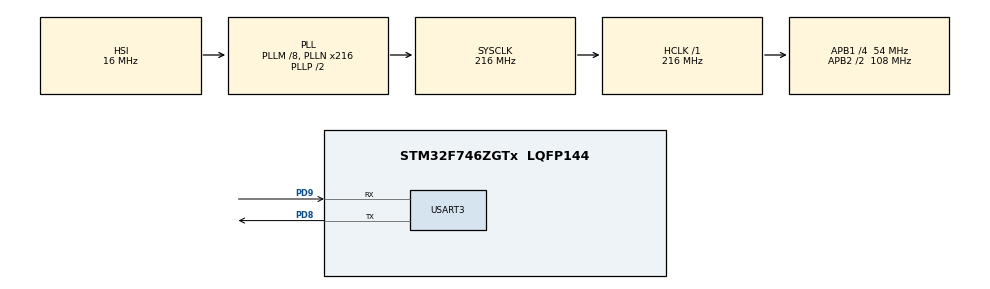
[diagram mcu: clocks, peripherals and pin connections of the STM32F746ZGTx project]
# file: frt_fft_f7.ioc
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CORTEX_M7.CPU_DCache=Enabled
CORTEX_M7.CPU_ICache=Enabled
CORTEX_M7.PREFETCH_ENABLE=1
CORTEX_M7.default_mode_Activation=1
FREERTOS.Tasks01=defaultTask,24,256,StartDefaultTask,Default,NULL,Dynamic,NULL,NULL
FREERTOS.configENABLE_FPU=1
FREERTOS.configUSE_NEWLIB_REENTRANT=1
Mcu.Family=STM32F7
Mcu.Name=STM32F746ZGTx
Mcu.Package=LQFP144
NVIC.PriorityGroup=NVIC_PRIORITYGROUP_4
NVIC.TIM1_UP_TIM10_IRQn=true\:15\:0\:false\:false\:true\:false\:false\:true\:true
NVIC.TimeBase=TIM1_UP_TIM10_IRQn
NVIC.TimeBaseIP=TIM1
PD8.Mode=Asynchronous
PD8.Signal=USART3_TX
PD9.Mode=Asynchronous
PD9.Signal=USART3_RX
ProjectManager.HeapSize=0x200
ProjectManager.StackSize=0x400
ProjectManager.TargetToolchain=STM32CubeIDE
RCC.AHBFreq_Value=216000000
RCC.APB1CLKDivider=RCC_HCLK_DIV4
RCC.APB1Freq_Value=54000000
RCC.APB1TimFreq_Value=108000000
RCC.APB2CLKDivider=RCC_HCLK_DIV2
RCC.APB2Freq_Value=108000000
RCC.APB2TimFreq_Value=216000000
RCC.CortexFreq_Value=216000000
RCC.HCLKFreq_Value=216000000
RCC.HSE_VALUE=25000000
RCC.HSI_VALUE=16000000
RCC.LSE_VALUE=32768
RCC.PLLM=8
RCC.PLLN=216
RCC.SYSCLKFreq_VALUE=216000000
RCC.SYSCLKSource=RCC_SYSCLKSOURCE_PLLCLK
RCC.USBFreq_Value=216000000
RCC.VCOOutputFreq_Value=432000000
USART3.VirtualMode-Asynchronous=VM_ASYNC
VP_FREERTOS_VS_CMSIS_V2.Mode=CMSIS_V2
VP_SYS_VS_tim1.Mode=TIM1
VP_TIM2_VS_ClockSourceINT.Mode=Internal
board=custom

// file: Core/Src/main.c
/* USER CODE BEGIN Header */
/**
 ******************************************************************************
 * @file           : main.c
 * @brief          : Main program body
 ******************************************************************************
 * @attention
 *
 * Copyright (c) 2025 STMicroelectronics.
 * All rights reserved.
 *
 * This software is licensed under terms that can be found in the LICENSE file
 * in the root directory of this software component.
 * If no LICENSE file comes with this software, it is provided AS-IS.
 *
 ******************************************************************************
 */
/* USER CODE END Header */
#include "main.h"
#include "cmsis_os.h"

/* USER CODE BEGIN Includes */
#include "twiddle1024.h"
/* USER CODE END Includes */

/* USER CODE BEGIN PD */
#define N_FFT          1024      // Dimensione FFT (reale)
#define NUM_ITER       100      // Numero di iterazioni per il benchmark
/* USER CODE END PD */

TIM_HandleTypeDef htim2;

UART_HandleTypeDef huart3;

/* Definitions for defaultTask */
osThreadId_t defaultTaskHandle;
const osThreadAttr_t defaultTask_attributes = {
  .name = "defaultTask",
  .stack_size = 256 * 4,
  .priority = (osPriority_t) osPriorityNormal,
};
/* USER CODE BEGIN PV */
// Buffer complesso: [re0, im0, re1, im1, ...]
static float buf[2 * N_FFT];

volatile uint32_t total_cycles = 0;
volatile uint32_t avg_cycles   = 0;
/* USER CODE END PV */

void SystemClock_Config(void);
static void MPU_Config(void);
static void MX_GPIO_Init(void);
static void MX_TIM2_Init(void);
static void MX_USART3_UART_Init(void);
void StartDefaultTask(void *argument);

/* USER CODE BEGIN 0 */
static void fft_init(void)
{
    for (int i = 0; i < N_FFT; ++i) {
        float x = (float)i;
        buf[2 * i + 0] = x;
        buf[2 * i + 1] = 0.5f * x;
    }
}

static void bit_reverse(float *b)
{
    int j = 0;
    for (int i = 0; i < N_FFT; ++i) {
        if (i < j) {
            float tr = b[2*i+0];
            float ti = b[2*i+1];
            b[2*i+0]  = b[2*j+0];
            b[2*i+1]  = b[2*j+1];
            b[2*j+0]  = tr;
            b[2*j+1]  = ti;
        }
        int bit = N_FFT >> 1;
        while (j & bit) { j ^= bit; bit >>= 1; }
        j |= bit;
    }
}

static void fft_radix2(float *b)
{
    bit_reverse(b);

    for (int len = 2; len <= N_FFT; len <<= 1) {
        int half_len = len >> 1;
        int stride   = N_FFT / len;

        for (int i = 0; i < N_FFT; i += len) {
            for (int j = 0; j < half_len; j++) {
                int idx1 = i + j;
                int idx2 = idx1 + half_len;
                int k    = j * stride;

                float wr = twiddle_cos[k];
                float wi = twiddle_sin[k];

                float xr = b[2*idx2+0];
                float xi = b[2*idx2+1];

                float tr = wr*xr - wi*xi;
                float ti = wr*xi + wi*xr;

                float ur = b[2*idx1+0];
                float ui = b[2*idx1+1];

                b[2*idx1+0] = ur + tr;
                b[2*idx1+1] = ui + ti;
                b[2*idx2+0] = ur - tr;
                b[2*idx2+1] = ui - ti;
            }
        }
    }
}

void fft_bench(int iterations)
{
    for (int k = 0; k < iterations; ++k) {
        fft_radix2(buf);

    }
}

int _write(int file, char *ptr, int len)
{
	HAL_UART_Transmit(&huart3, (uint8_t*)ptr, len, HAL_MAX_DELAY);
	return len;
}

void run_benchmark(void)
{
    fft_init();

    uint32_t start = __HAL_TIM_GET_COUNTER(&htim2);
    fft_bench(NUM_ITER);
    uint32_t end   = __HAL_TIM_GET_COUNTER(&htim2);

    uint32_t ticks = end - start;       // ticks @108 MHz
    // Converti a cicli CPU (216 MHz): *2
    total_cycles = ticks * 2u;
    avg_cycles   = total_cycles / NUM_ITER;

    printf("HAL_RCC_GetSysClockFreq() = %lu Hz\r\n",
           (unsigned long)HAL_RCC_GetSysClockFreq());
    printf("HAL_RCC_GetPCLK1Freq()    = %lu Hz\r\n",
           (unsigned long)HAL_RCC_GetPCLK1Freq());
    printf("TIM2 ticks=%lu\r\n", (unsigned long)ticks);
    printf("total_cycles=%lu avg_cycles=%lu\r\n",
           (unsigned long)total_cycles,
           (unsigned long)avg_cycles);
}
/* USER CODE END 0 */

int main(void)
{

  /* MPU Configuration--------------------------------------------------------*/
  MPU_Config();

  /* Enable the CPU Cache */

  /* Enable I-Cache---------------------------------------------------------*/
  SCB_EnableICache();

  /* Enable D-Cache---------------------------------------------------------*/
  SCB_EnableDCache();

  /* MCU Configuration--------------------------------------------------------*/

  /* Reset of all peripherals, Initializes the Flash interface and the Systick. */
  HAL_Init();

  /* Configure the system clock */
  SystemClock_Config();

  /* Initialize all configured peripherals */
  MX_GPIO_Init();
  MX_TIM2_Init();
  MX_USART3_UART_Init();

  /* Init scheduler */
  osKernelInitialize();

  /* Create the thread(s) */
  /* creation of defaultTask */
  defaultTaskHandle = osThreadNew(StartDefaultTask, NULL, &defaultTask_attributes);

  /* Start scheduler */
  osKernelStart();

  /* We should never get here as control is now taken by the scheduler */

  /* Infinite loop */
	while (1)
	{

	}
}

void SystemClock_Config(void)
{
  RCC_OscInitTypeDef RCC_OscInitStruct = {0};
  RCC_ClkInitTypeDef RCC_ClkInitStruct = {0};

  /** Configure the main internal regulator output voltage
  */
  __HAL_RCC_PWR_CLK_ENABLE();
  __HAL_PWR_VOLTAGESCALING_CONFIG(PWR_REGULATOR_VOLTAGE_SCALE1);

  /** Initializes the RCC Oscillators according to the specified parameters
  * in the RCC_OscInitTypeDef structure.
  */
  RCC_OscInitStruct.OscillatorType = RCC_OSCILLATORTYPE_HSI;
  RCC_OscInitStruct.HSIState = RCC_HSI_ON;
  RCC_OscInitStruct.HSICalibrationValue = RCC_HSICALIBRATION_DEFAULT;
  RCC_OscInitStruct.PLL.PLLState = RCC_PLL_ON;
  RCC_OscInitStruct.PLL.PLLSource = RCC_PLLSOURCE_HSI;
  RCC_OscInitStruct.PLL.PLLM = 8;
  RCC_OscInitStruct.PLL.PLLN = 216;
  RCC_OscInitStruct.PLL.PLLP = RCC_PLLP_DIV2;
  RCC_OscInitStruct.PLL.PLLQ = 2;
  if (HAL_RCC_OscConfig(&RCC_OscInitStruct) != HAL_OK)
  {
    Error_Handler();
  }

  /** Activate the Over-Drive mode
  */
  if (HAL_PWREx_EnableOverDrive() != HAL_OK)
  {
    Error_Handler();
  }

  /** Initializes the CPU, AHB and APB buses clocks
  */
  RCC_ClkInitStruct.ClockType = RCC_CLOCKTYPE_HCLK|RCC_CLOCKTYPE_SYSCLK
                              |RCC_CLOCKTYPE_PCLK1|RCC_CLOCKTYPE_PCLK2;
  RCC_ClkInitStruct.SYSCLKSource = RCC_SYSCLKSOURCE_PLLCLK;
  RCC_ClkInitStruct.AHBCLKDivider = RCC_SYSCLK_DIV1;
  RCC_ClkInitStruct.APB1CLKDivider = RCC_HCLK_DIV4;
  RCC_ClkInitStruct.APB2CLKDivider = RCC_HCLK_DIV2;

  if (HAL_RCC_ClockConfig(&RCC_ClkInitStruct, FLASH_LATENCY_7) != HAL_OK)
  {
    Error_Handler();
  }
}

static void MX_TIM2_Init(void)
{

  TIM_ClockConfigTypeDef sClockSourceConfig = {0};
  TIM_MasterConfigTypeDef sMasterConfig = {0};

  htim2.Instance = TIM2;
  htim2.Init.Prescaler = 0;
  htim2.Init.CounterMode = TIM_COUNTERMODE_UP;
  htim2.Init.Period = 4294967295;
  htim2.Init.ClockDivision = TIM_CLOCKDIVISION_DIV1;
  htim2.Init.AutoReloadPreload = TIM_AUTORELOAD_PRELOAD_DISABLE;
  if (HAL_TIM_Base_Init(&htim2) != HAL_OK)
  {
    Error_Handler();
  }
  sClockSourceConfig.ClockSource = TIM_CLOCKSOURCE_INTERNAL;
  if (HAL_TIM_ConfigClockSource(&htim2, &sClockSourceConfig) != HAL_OK)
  {
    Error_Handler();
  }
  sMasterConfig.MasterOutputTrigger = TIM_TRGO_RESET;
  sMasterConfig.MasterSlaveMode = TIM_MASTERSLAVEMODE_DISABLE;
  if (HAL_TIMEx_MasterConfigSynchronization(&htim2, &sMasterConfig) != HAL_OK)
  {
    Error_Handler();
  }
  /* USER CODE BEGIN TIM2_Init 2 */
  HAL_TIM_Base_Start(&htim2);
  /* USER CODE END TIM2_Init 2 */

}

static void MX_USART3_UART_Init(void)
{

  huart3.Instance = USART3;
  huart3.Init.BaudRate = 115200;
  huart3.Init.WordLength = UART_WORDLENGTH_8B;
  huart3.Init.StopBits = UART_STOPBITS_1;
  huart3.Init.Parity = UART_PARITY_NONE;
  huart3.Init.Mode = UART_MODE_TX_RX;
  huart3.Init.HwFlowCtl = UART_HWCONTROL_NONE;
  huart3.Init.OverSampling = UART_OVERSAMPLING_16;
  huart3.Init.OneBitSampling = UART_ONE_BIT_SAMPLE_DISABLE;
  huart3.AdvancedInit.AdvFeatureInit = UART_ADVFEATURE_NO_INIT;
  if (HAL_UART_Init(&huart3) != HAL_OK)
  {
    Error_Handler();
  }

}

static void MX_GPIO_Init(void)
{

  /* GPIO Ports Clock Enable */
  __HAL_RCC_GPIOD_CLK_ENABLE();

}

void StartDefaultTask(void *argument)
{
  /* USER CODE BEGIN 5 */
	SysTick->CTRL = 0;   // disabilita SysTick
	__disable_irq();     // opzionale se vuoi togliere tutte le IRQ
	printf("FreeRTOS F7\r\n");
	run_benchmark();

	/* Infinite loop */
	for(;;)
	{
		osDelay(1);
	}
  /* USER CODE END 5 */
}

 /* MPU Configuration */

void MPU_Config(void)
{
  MPU_Region_InitTypeDef MPU_InitStruct = {0};

  /* Disables the MPU */
  HAL_MPU_Disable();

  /** Initializes and configures the Region and the memory to be protected
  */
  MPU_InitStruct.Enable = MPU_REGION_ENABLE;
  MPU_InitStruct.Number = MPU_REGION_NUMBER0;
  MPU_InitStruct.BaseAddress = 0x0;
  MPU_InitStruct.Size = MPU_REGION_SIZE_4GB;
  MPU_InitStruct.SubRegionDisable = 0x87;
  MPU_InitStruct.TypeExtField = MPU_TEX_LEVEL0;
  MPU_InitStruct.AccessPermission = MPU_REGION_NO_ACCESS;
  MPU_InitStruct.DisableExec = MPU_INSTRUCTION_ACCESS_DISABLE;
  MPU_InitStruct.IsShareable = MPU_ACCESS_SHAREABLE;
  MPU_InitStruct.IsCacheable = MPU_ACCESS_NOT_CACHEABLE;
  MPU_InitStruct.IsBufferable = MPU_ACCESS_NOT_BUFFERABLE;

  HAL_MPU_ConfigRegion(&MPU_InitStruct);
  /* Enables the MPU */
  HAL_MPU_Enable(MPU_PRIVILEGED_DEFAULT);

}

void HAL_TIM_PeriodElapsedCallback(TIM_HandleTypeDef *htim)
{
  if (htim->Instance == TIM1)
  {
    HAL_IncTick();
  }
}

void Error_Handler(void)
{
	__disable_irq();
	while (1)
	{
	}
}
